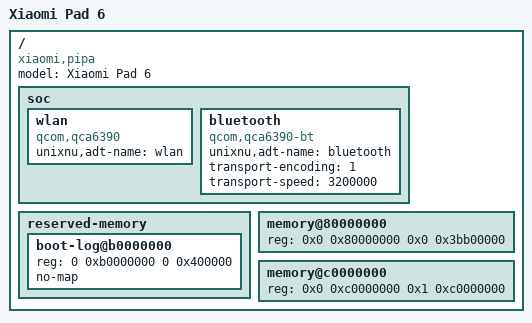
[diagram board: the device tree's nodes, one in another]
// SPDX-License-Identifier: BSD-2-Clause-Patent
// Board-level hardware description for the Xiaomi Pad 6 (pipa, SM8250-AC).
//
// This is the fallback tree of scripts/check-pipa.py. When a uefi-pipa checkout is present its
// Resources/DTBs/pipa.dtb is appended to the boot image instead, and this file is not compiled.
/dts-v1/;
/include/ "sm8250.dtsi"

/ {
    model = "Xiaomi Pad 6";
    compatible = "xiaomi,pipa", "qcom,kona";

    // Export the radios under /soc (/arm-io in ADT) before launchd evaluates wifid's device-tree condition.
    // WifiProbe owns PCIe0 resources and fills local-mac-address at runtime; BluetoothProbe drives the BT pins.
    // status = "okay" only keeps the ADT locator nodes present: neither driver starts until sheng-wifi=4 /
    // sheng-bluetooth=1 is set in board.toml, which stays unset until the radios are verified on pipa.
    soc {
        wlan {
            compatible = "qcom,qca6390";
            unixnu,adt-name = "wlan";
            status = "okay";
        };

        bluetooth {
            device_type = "bluetooth";
            compatible = "qcom,qca6390-bt";
            unixnu,adt-name = "bluetooth";
            transport-encoding = <1>;
            transport-speed = <3200000>;
            status = "okay";
        };
    };

    // The stock kernel reserves 4 MiB at 0xB0000000 for ramoops (console then pmsg, no ECC). BootRamoops.c
    // maps the first 512 KiB as its console zone; the firmware's RamoopsLogLib writes the same region.
    // Do not export the whole reservation as an arm-io device/MMIO alias.
    reserved-memory {
        #address-cells = <2>;
        #size-cells = <2>;
        ranges;
        boot-log@b0000000 {
            reg = <0 0xb0000000 0 0x400000>;
            no-map;
        };
    };

    // Measured on the target 8 GB unit (Xiaomi pipa device tree, read from /proc/device-tree/memory on the booted
    // ColorOS port): two ranges, ending at 0x280000000. The bootloader reserves the 0xbbb00000..0xc0000000 hole,
    // which sits inside the single dram-base/dram-size span XNU receives. The 16 GB reference unit additionally had
    // an 8 GiB bank at 32 GiB; this unit does not, so there is no memory@800000000 node.
    memory@80000000 {
        device_type = "memory";
        reg = <0x0 0x80000000 0x0 0x3bb00000>;
        status = "okay";
    };

    memory@c0000000 {
        device_type = "memory";
        reg = <0x0 0xc0000000 0x1 0xc0000000>;
        status = "okay";
    };
};
